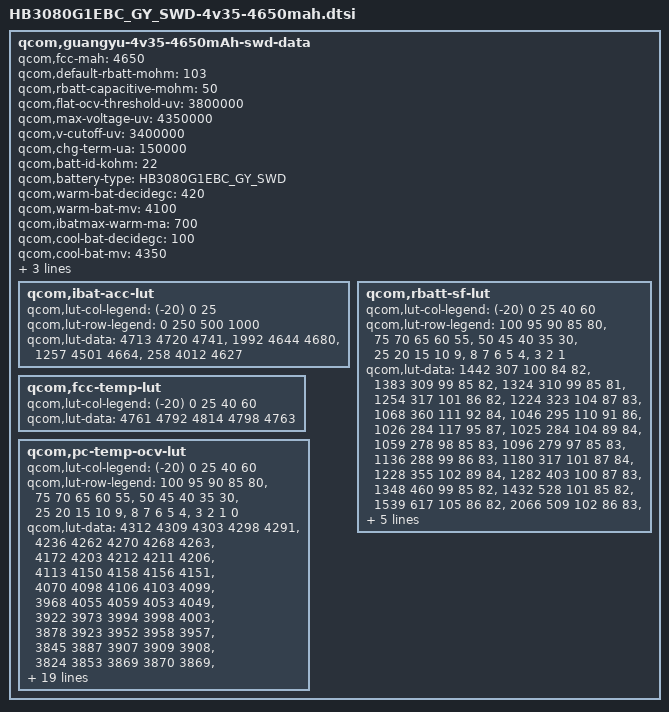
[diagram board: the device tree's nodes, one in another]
/* Copyright (c) 2013, The Linux Foundation. All rights reserved.
 *
 * This program is free software; you can redistribute it and/or modify
 * it under the terms of the GNU General Public License version 2 and
 * only version 2 as published by the Free Software Foundation.
 *
 * This program is distributed in the hope that it will be useful,
 * but WITHOUT ANY WARRANTY; without even the implied warranty of
 * MERCHANTABILITY or FITNESS FOR A PARTICULAR PURPOSE.  See the
 * GNU General Public License for more details.
 */
qcom,guangyu-4v35-4650mAh-swd-data {
	qcom,fcc-mah = <4650>;
	qcom,default-rbatt-mohm = <103>;
	qcom,rbatt-capacitive-mohm = <50>;
	qcom,flat-ocv-threshold-uv = <3800000>;
	qcom,max-voltage-uv = <4350000>;
	qcom,v-cutoff-uv = <3400000>;
	qcom,chg-term-ua = <150000>;
	qcom,batt-id-kohm = <22>;
	qcom,battery-type = "HB3080G1EBC_GY_SWD";

	qcom,warm-bat-decidegc = <420>;
	qcom,warm-bat-mv = <4100>;
	qcom,ibatmax-warm-ma = <700>;

	qcom,cool-bat-decidegc = <100>;
	qcom,cool-bat-mv = <4350>;
	qcom,ibatmax-cool-ma = <600>;

	qcom,hot-bat-decidegc = <520>;
	qcom,cold-bat-decidegc = <0>;
	qcom,ibat-acc-lut {
	    qcom,lut-col-legend = <(-20) 0 25>;
		qcom,lut-row-legend = <0 250 500 1000>;
		qcom,lut-data = <4713 4720 4741>,
		                <1992 4644 4680>,
						<1257 4501 4664>,
						<258 4012 4627>;
	};
	qcom,rbatt-sf-lut {
		qcom,lut-col-legend = <(-20) 0 25 40 60>;
		qcom,lut-row-legend = 
		    <100 95 90 85 80>,
				<75 70 65 60 55>,
				<50 45 40 35 30>,
				<25 20 15 10 9>,
				<8 7 6 5 4>,
				<3 2 1>;
		qcom,lut-data = <1442 307 100 84 82>,
				<1383 309 99 85 82>,
				<1324 310 99 85 81>,
				<1254 317 101 86 82>,
				<1224 323 104 87 83>,
				<1068 360 111 92 84>,
				<1046 295 110 91 86>,
				<1026 284 117 95 87>,
				<1025 284 104 89 84>,
				<1059 278 98 85 83>,
				<1096 279 97 85 83>,
				<1136 288 99 86 83>,
				<1180 317 101 87 84>,
				<1228 355 102 89 84>,
				<1282 403 100 87 83>,
				<1348 460 99 85 82>,
				<1432 528 101 85 82>,
				<1539 617 105 86 82>,
				<2066 509 102 86 83>,
				<2224 555 102 87 86>,
				<2378 600 102 88 85>,
				<2531 659 104 88 84>,
				<2710 737 104 88 83>,
				<2902 800 103 86 82>,
				<3160 858 106 87 83>,
				<3431 979 109 88 85>,
				<3795 1194 115 89 85>,
				<4335 1458 143 93 86>;
	};

	qcom,fcc-temp-lut {
		qcom,lut-col-legend = <(-20) 0 25 40 60>;
		qcom,lut-data = <4761 4792 4814 4798 4763>;
	};

	qcom,pc-temp-ocv-lut {
		qcom,lut-col-legend = <(-20) 0 25 40 60>;
		qcom,lut-row-legend =
	    <100 95 90 85 80>,
				<75 70 65 60 55>,
				<50 45 40 35 30>,
				<25 20 15 10 9>,
				<8 7 6 5 4>,
				<3 2 1 0>;
		qcom,lut-data = 
		    <4312 4309 4303 4298 4291>,
				<4236 4262 4270 4268 4263>,
				<4172 4203 4212 4211 4206>,
				<4113 4150 4158 4156 4151>,
				<4070 4098 4106 4103 4099>,
				<3968 4055 4059 4053 4049>,
				<3922 3973 3994 3998 4003>,
				<3878 3923 3952 3958 3957>,
				<3845 3887 3907 3909 3908>,
				<3824 3853 3869 3870 3869>,
				<3808 3824 3841 3842 3841>,
				<3793 3803 3818 3819 3818>,
				<3779 3790 3800 3801 3799>,
				<3765 3780 3783 3784 3782>,
				<3751 3768 3767 3765 3758>,
				<3737 3753 3751 3743 3731>,
				<3724 3734 3731 3724 3711>,
				<3706 3710 3706 3700 3688>,
				<3677 3689 3689 3682 3670>,
				<3669 3686 3687 3681 3669>,
				<3658 3682 3685 3679 3666>,
				<3643 3674 3680 3675 3662>,
				<3626 3661 3667 3664 3649>,
				<3602 3638 3637 3637 3620>,
				<3574 3599 3593 3596 3580>,
				<3534 3546 3537 3544 3528>,
				<3478 3475 3462 3475 3459>,
				<3399 3368 3350 3374 3359>,
				<3200 3200 3200 3200 3200>;
	};
};
